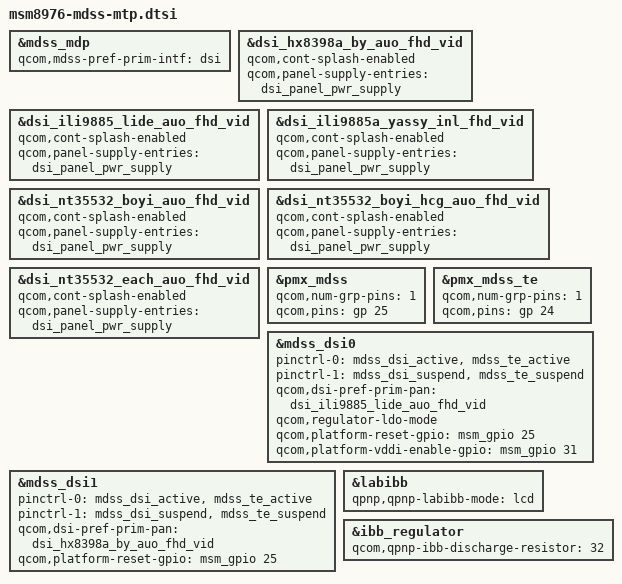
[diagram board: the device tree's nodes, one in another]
/*
 * Copyright (c) 2015, The Linux Foundation. All rights reserved.
 *
 * This program is free software; you can redistribute it and/or modify
 * it under the terms of the GNU General Public License version 2 and
 * only version 2 as published by the Free Software Foundation.
 *
 * This program is distributed in the hope that it will be useful,
 * but WITHOUT ANY WARRANTY; without even the implied warranty of
 * MERCHANTABILITY or FITNESS FOR A PARTICULAR PURPOSE.  See the
 * GNU General Public License for more details.
 */

&mdss_mdp {
	qcom,mdss-pref-prim-intf = "dsi";
};

&dsi_hx8398a_by_auo_fhd_vid {
	qcom,cont-splash-enabled;
	qcom,panel-supply-entries = <&dsi_panel_pwr_supply>;
};

&dsi_ili9885_lide_auo_fhd_vid {
	qcom,cont-splash-enabled;
	qcom,panel-supply-entries = <&dsi_panel_pwr_supply>;
};


&dsi_ili9885a_yassy_inl_fhd_vid {
	qcom,cont-splash-enabled;
	qcom,panel-supply-entries = <&dsi_panel_pwr_supply>;
};

&dsi_nt35532_boyi_auo_fhd_vid {
	qcom,cont-splash-enabled;
	qcom,panel-supply-entries = <&dsi_panel_pwr_supply>;
};

&dsi_nt35532_boyi_hcg_auo_fhd_vid {
	qcom,cont-splash-enabled;
	qcom,panel-supply-entries = <&dsi_panel_pwr_supply>;
};

&dsi_nt35532_each_auo_fhd_vid {
	qcom,cont-splash-enabled;
	qcom,panel-supply-entries = <&dsi_panel_pwr_supply>;
};

&pmx_mdss {
	qcom,num-grp-pins = <1>;
	qcom,pins = <&gp 25>;
};

&pmx_mdss_te {
	qcom,num-grp-pins = <1>;
	qcom,pins = <&gp 24>;
};

&mdss_dsi0 {
	pinctrl-names = "mdss_default", "mdss_sleep";
	pinctrl-0 = <&mdss_dsi_active &mdss_te_active>;
	pinctrl-1 = <&mdss_dsi_suspend &mdss_te_suspend>;
	qcom,dsi-pref-prim-pan = <&dsi_ili9885_lide_auo_fhd_vid>;
	qcom,regulator-ldo-mode;
	qcom,platform-reset-gpio = <&msm_gpio 25 0>;
	qcom,platform-vddi-enable-gpio = <&msm_gpio 31 0>;
};

&mdss_dsi1 {
	pinctrl-names = "mdss_default", "mdss_sleep";
	pinctrl-0 = <&mdss_dsi_active &mdss_te_active>;
	pinctrl-1 = <&mdss_dsi_suspend &mdss_te_suspend>;
	qcom,dsi-pref-prim-pan = <&dsi_hx8398a_by_auo_fhd_vid>;

	qcom,platform-reset-gpio = <&msm_gpio 25 0>;
};

&labibb {
	status = "ok";
	qpnp,qpnp-labibb-mode = "lcd";
};

&ibb_regulator {
	qcom,qpnp-ibb-discharge-resistor = <32>;
};
